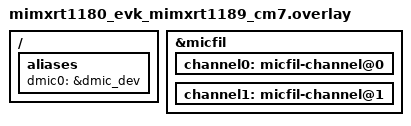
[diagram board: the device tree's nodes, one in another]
/*
 * SPDX-FileCopyrightText: Copyright 2026 NXP
 * SPDX-License-Identifier: Apache-2.0
 */

/ {
	aliases {
		dmic0 = &dmic_dev;
	};
};

dmic_dev: &micfil {
	status = "okay";

	channel0: micfil-channel@0 {
		status = "okay";
	};

	channel1: micfil-channel@1 {
		status = "okay";
	};
};
